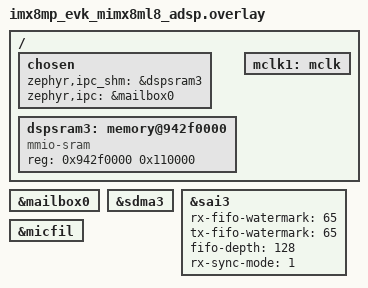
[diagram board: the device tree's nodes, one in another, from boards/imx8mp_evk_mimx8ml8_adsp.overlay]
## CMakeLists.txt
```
cmake_minimum_required(VERSION 3.20.0)

find_package(Zephyr REQUIRED HINTS $ENV{ZEPHYR_BASE})

project(audioreach_engine_sample)

target_sources(app PRIVATE src/main.c)

target_link_libraries(app PUBLIC spf)

set(INC_PATH ${ZEPHYR_AUDIOREACH_ENGINE_MODULE_DIR})

target_include_directories(app PRIVATE
    ${INC_PATH}/fwk/spf/utils/cmn/inc
    ${INC_PATH}/fwk/platform/posal/inc
    ${INC_PATH}/fwk/platform/posal/inc/linux/
    ${INC_PATH}/fwk/platform/posal/inc/linux/stringl
    ${INC_PATH}/fwk/api/ar_utils
    ${INC_PATH}/fwk/api/ar_utils/generic/
    ${INC_PATH}/ar_osal/api
    ${INC_PATH}/gpr/api
    )

zephyr_include_directories()
```

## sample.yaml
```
sample:
  description: AudioReach Engine initialization sample for Zephyr RTOS
  name: audioreach_engine_sample
common:
  tags:
    - audio
    - signal-processing
  modules:
    - audioreach-engine
```

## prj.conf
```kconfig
# ZEPHYR CORE CONFIGURATION
CONFIG_MAIN_STACK_SIZE=32768
CONFIG_HEAP_MEM_POOL_SIZE=32768
CONFIG_IDLE_STACK_SIZE=4096
CONFIG_ISR_STACK_SIZE=4096

# INTER-PROCESSOR COMMUNICATION (OpenAMP/RPMsg)
CONFIG_IPM=y
CONFIG_OPENAMP=y
CONFIG_OPENAMP_RSC_TABLE_NUM_RPMSG_BUFF=32
CONFIG_OPENAMP_RSC_TABLE=y
CONFIG_OPENAMP_MASTER=n

# POSIX API SUPPORT
CONFIG_POSIX_API=y
CONFIG_POSIX_THREADS_EXT=y
CONFIG_POSIX_PRIORITY_SCHEDULING=y

# POSIX Thread Limits
CONFIG_POSIX_THREAD_THREADS_MAX=7
CONFIG_POSIX_THREAD_KEYS_MAX=7
CONFIG_MAX_PTHREAD_MUTEX_COUNT=70
CONFIG_MAX_PTHREAD_SPINLOCK_COUNT=10
CONFIG_MAX_PTHREAD_COND_COUNT=20

# DYNAMIC THREADING
CONFIG_DYNAMIC_THREAD=y
CONFIG_DYNAMIC_THREAD_POOL_SIZE=10
CONFIG_DYNAMIC_THREAD_STACK_SIZE=32768

# LOGGING CONFIGURATION
CONFIG_LOG=y
CONFIG_LOG_DEFAULT_LEVEL=1
CONFIG_LOG_BACKEND_UART=y
CONFIG_LOG_BUFFER_SIZE=16384
CONFIG_LOG_PROCESS_THREAD_STACK_SIZE=16384
CONFIG_DEBUG_THREAD_INFO=y
CONFIG_THREAD_NAME=y

# C LIBRARY
CONFIG_NEWLIB_LIBC=y

# SHELL CONFIGURATION
CONFIG_SHELL=y
CONFIG_SHELL_BACKEND_RPMSG=y

# AUDIOREACH ENGINE CONFIGURATION
CONFIG_PROC_DOMAIN="ADSP"
CONFIG_ARCH_ZEPHYR=y
CONFIG_SHARED_INTERRUPTS=y

# AudioReach Features - Disabled for minimal build
CONFIG_ALSA_DEVICE_SINK=n
CONFIG_ALSA_DEVICE_SOURCE=n
CONFIG_NXP_DEVICE_SINK=y
CONFIG_SH_MEM_PULL_MODE=n
CONFIG_SH_MEM_PUSH_MODE=n
CONFIG_LATENCY=n
CONFIG_SYNC=n
CONFIG_SPR=n
CONFIG_SPLITTER=n
CONFIG_DATA_MARKER=n
CONFIG_PRIORITY_SYNC=n
CONFIG_MUX_DEMUX=n
CONFIG_ECHO_CANCELLATION=n
CONFIG_ENCODER=n
CONFIG_CHMIXER=n
CONFIG_PCM_CNV=n
CONFIG_IRM=n
CONFIG_MSIIR=n
CONFIG_IIR_MBDRC=n
CONFIG_SAL=n
CONFIG_GAIN=n
CONFIG_MODULES_DEBUG=n

# Container Configuration
CONFIG_SPL_CNTR=n
CONFIG_SPECIAL_TOPOLOGY=n
CONFIG_WR_SH_MEM_EP=y
CONFIG_RD_SH_MEM_EP=n
CONFIG_PLACEHOLDER_ENC_DEC=n

# POSAL Configuration
CONFIG_COMPILE_POSAL=y
CONFIG_DLS_DATA_LOGGING=y

# Signal Processing Framework Modules
CONFIG_EXAMPLE_GAIN=y
CONFIG_DATA_LOGGING=y
CONFIG_SISO_RAT=y

CONFIG_MODULES=y
```

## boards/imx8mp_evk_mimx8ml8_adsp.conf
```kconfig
CONFIG_LOG_PRINTK=n
CONFIG_IPM_IMX_MAX_DATA_SIZE_16=n
CONFIG_IPM_IMX_MAX_DATA_SIZE_4=y
CONFIG_OPENAMP_WITH_DCACHE=y
CONFIG_IPM_IMX_FW_READY_REPLY=y
CONFIG_POSAL_MMAP_NO_MMU=y
CONFIG_DAI=y
CONFIG_DMA=y
CONFIG_DAI_NXP_SAI=y
CONFIG_DMA_NXP_SDMA=y
CONFIG_SAI_HAS_MCLK_CONFIG_OPTION=y
CONFIG_CLOCK_CONTROL_FIXED_RATE_CLOCK=y
```

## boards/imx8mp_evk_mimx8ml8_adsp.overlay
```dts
/*
 * Copyright (c) 2023 NXP
 *
 * SPDX-License-Identifier: Apache-2.0
 */

/ {
	chosen {
		/*
		 * shared memory reserved for the inter-processor communication
		 */
		zephyr,ipc_shm = &dspsram3;
		zephyr,ipc = &mailbox0;
	};

	dspsram3: memory@942f0000 {
		compatible = "mmio-sram";
		reg = <0x942f0000 0x110000>;
	};

	mclk1: mclk {
		status = "okay";
	};
};

&mailbox0 {
	status = "okay";
};

&sdma3 {
	status = "okay";
};

&sai3 {
	rx-fifo-watermark = <65>;
	tx-fifo-watermark = <65>;
	fifo-depth = <128>;
	rx-sync-mode = <1>;
	status = "okay";
};

&micfil {
	status = "okay";
};
```

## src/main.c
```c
/*
 * Copyright (c) Qualcomm Technologies, Inc. and/or its subsidiaries.
 * SPDX-License-Identifier: BSD-3-Clause
 */

#include <stdio.h>
#include <posal.h>
#include <spf_main.h>
#include <gpr_api.h>

int main(void)
{
    int rc = 0;
    posal_init();

    rc = gpr_init();
    if (0 != rc) {
        printf("gpr_init() failed with status %d\n", rc);
        return rc;
    }

    rc = spf_framework_pre_init();
    if (0 != rc) {
        printf("spf_framework_pre_init() failed with status %d\n", rc);
        return rc;
    }

    rc = spf_framework_post_init();
    if (0 != rc) {
        printf("spf_framework_post_init() failed with status %d\n", rc);
        return rc;
    }

    printf("spf framework initialized.\n", rc);

    return 0;
}
```
